# SA3_SS0_RINGACC_0_IPCSS_RINGACC_CFG register map
Vendor: Texas Instruments
Peripheral module from a debugger description file (folder am62P).
Registers are 32-bit, read-write, reset 0x0 unless marked. A register's access mark holds for its fields unless they carry their own. Offsets are as the file gives them; lines under a group give offsets from that group; [hi:lo] are bit positions; {n}, {i} and the like mark numbered series; 'fields as' and 'values as' point back to an identical list; <NAME> marks a mode.

## SA3_SS0_RINGACC_0_IPCSS_RINGACC_CFG
0x40 IPCSS__RINGACC_CFG__CFG_BA_LO — The Tx Ring Base Address Lo Register contains the 32 LSBs of the base address for the ring which is used to hand off pending work for the channel from the Host. The base address must be aligned to the element size of the ring, or to double the element size of the ring if the qmode is CREDENTIALS or QM modes. A write to this register will reset the associated ring to clear the occupancies and reset the pointers.
  [31:0] ADDR_LO — Tx Ring base address (LSBs)
0x44 IPCSS__RINGACC_CFG__CFG_BA_HI — The Tx Ring Base Address Hi Register contains the 16 MSBs of the base address for the ring which is used to hand off pending work for the channel from the Host. The base address must be aligned to the element size of the ring, or to double the element size of the ring if the qmode is CREDENTIALS or QM modes. A write to this register will reset the associated ring to clear the occupancies and reset the pointers.
  [15:0] ADDR_HI — Tx Ring base address (MSBs)
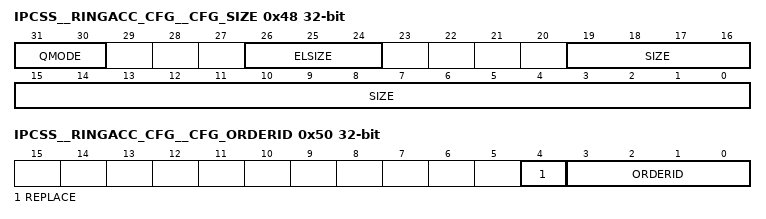
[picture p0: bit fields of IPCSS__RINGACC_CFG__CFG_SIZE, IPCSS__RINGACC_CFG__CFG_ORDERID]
0x48 IPCSS__RINGACC_CFG__CFG_SIZE — The Tx Ring Size Register contains the element size and element counts for the ring which is used to hand off pending work for the channel from the Host. A write to this register will reset the associated ring to clear the occupancies and reset the pointers.
  [31:30] QMODE — Defines the mode for this ring or queue.
  [26:24] ELSIZE — Ring element size. This field is encoded as follows: 0 = 4 bytes 1 = 8 bytes 2 = 16 bytes 3 = 32 bytes 4 = 64 bytes 5 = 128 bytes 6 = 256 bytes 7 = RESERVED
  [19:0] SIZE — Tx Ring element count. This field configures the size of the ring in elements. For rings in CREDENTIALS or QM modes the size must be an even number.
0x4C IPCSS__RINGACC_CFG__CFG_EVT reset 0xFFFF — The Ring Event Register is an Output Event Steering 'OES' register that specifies the event number used to denote the occurrence of an up event [empty to not-empty] or a down event [non-empty to empty] for this ring.
  [15:0] EVT — Defines the event for this ring or queue.
0x50 IPCSS__RINGACC_CFG__CFG_ORDERID — The Ring OrderID Register contains the bus orderid value for the ring memory access.
  [4] REPLACE — Indicates to replace the bus orderid value for this ring or queue with the orderid MMR field. This allows control over the orderid value when it must be restricted due to the topology for QoS reasons. 0 = bypass and use the orderid from the source transaction for the destination transaction. 1 = use the orderid MMR field value for the destination transaction.
  [3:0] ORDERID — Defines the bus orderid value for this ring or queue.
